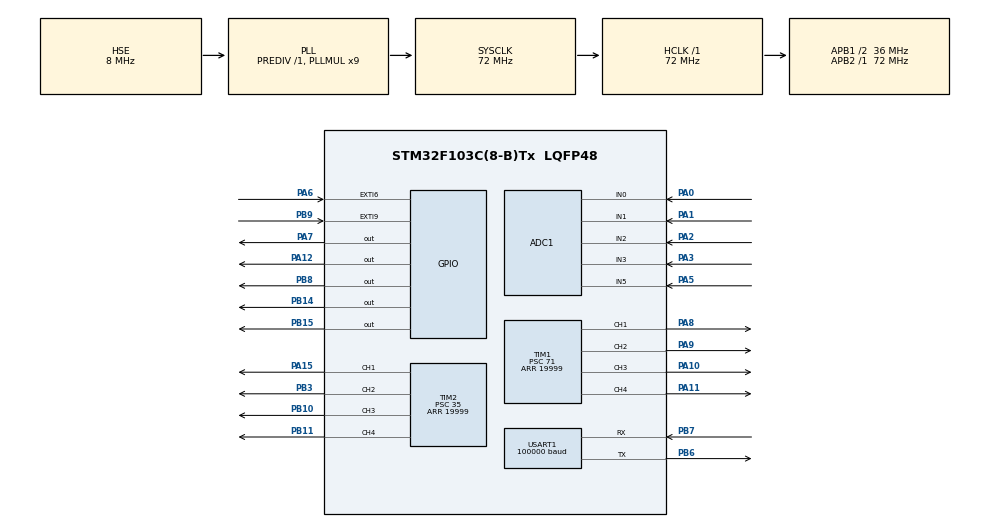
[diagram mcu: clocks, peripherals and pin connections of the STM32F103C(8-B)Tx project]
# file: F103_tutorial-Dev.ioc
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ADC1.Channel-0\#ChannelRegularConversion=ADC_CHANNEL_5
ADC1.NbrOfConversionFlag=1
ADC1.Rank-0\#ChannelRegularConversion=1
ADC1.SamplingTime-0\#ChannelRegularConversion=ADC_SAMPLETIME_1CYCLE_5
ADC1.master=1
Dma.Request0=USART1_RX
Dma.USART1_RX.0.Direction=DMA_PERIPH_TO_MEMORY
Dma.USART1_RX.0.Instance=DMA1_Channel5
Dma.USART1_RX.0.MemDataAlignment=DMA_MDATAALIGN_BYTE
Dma.USART1_RX.0.MemInc=DMA_MINC_ENABLE
Dma.USART1_RX.0.Mode=DMA_NORMAL
Dma.USART1_RX.0.PeriphDataAlignment=DMA_PDATAALIGN_BYTE
Dma.USART1_RX.0.PeriphInc=DMA_PINC_DISABLE
Dma.USART1_RX.0.Priority=DMA_PRIORITY_VERY_HIGH
FREERTOS.Tasks01=defaultTask,24,128,StartDefaultTask,Default,NULL,Dynamic,NULL,NULL
Mcu.Family=STM32F1
Mcu.Name=STM32F103C(8-B)Tx
Mcu.Package=LQFP48
NVIC.DMA1_Channel5_IRQn=true\:5\:0\:false\:false\:true\:true\:false\:true\:true
NVIC.EXTI9_5_IRQn=true\:5\:0\:false\:false\:true\:false\:true\:true\:true
NVIC.PriorityGroup=NVIC_PRIORITYGROUP_4
NVIC.TIM3_IRQn=true\:15\:0\:false\:false\:true\:false\:false\:true\:true
NVIC.TimeBase=TIM3_IRQn
NVIC.TimeBaseIP=TIM3
NVIC.USART1_IRQn=true\:5\:0\:false\:false\:true\:true\:true\:true\:true
PA0-WKUP.Signal=ADCx_IN0
PA1.Signal=ADCx_IN1
PA10.Signal=S_TIM1_CH3
PA11.Signal=S_TIM1_CH4
PA12.Signal=GPIO_Output
PA13.Mode=Serial_Wire
PA13.Signal=SYS_JTMS-SWDIO
PA14.Mode=Serial_Wire
PA14.Signal=SYS_JTCK-SWCLK
PA15.Signal=S_TIM2_CH1_ETR
PA2.Signal=ADCx_IN2
PA3.Signal=ADCx_IN3
PA5.Signal=ADCx_IN5
PA6.Signal=GPXTI6
PA7.Signal=GPIO_Output
PA8.Signal=S_TIM1_CH1
PA9.Signal=S_TIM1_CH2
PB10.Signal=S_TIM2_CH3
PB11.Signal=S_TIM2_CH4
PB14.Signal=GPIO_Output
PB15.Signal=GPIO_Output
PB3.Signal=S_TIM2_CH2
PB6.Mode=Asynchronous
PB6.Signal=USART1_TX
PB7.Mode=Asynchronous
PB7.Signal=USART1_RX
PB8.Signal=GPIO_Output
PB9.Signal=GPXTI9
PD0-OSC_IN.Mode=HSE-External-Oscillator
PD0-OSC_IN.Signal=RCC_OSC_IN
PD1-OSC_OUT.Mode=HSE-External-Oscillator
PD1-OSC_OUT.Signal=RCC_OSC_OUT
ProjectManager.HeapSize=0x200
ProjectManager.StackSize=0x400
ProjectManager.TargetToolchain=MDK-ARM V5.32
RCC.ADCPresc=RCC_ADCPCLK2_DIV6
RCC.AHBFreq_Value=72000000
RCC.APB1CLKDivider=RCC_HCLK_DIV2
RCC.APB1Freq_Value=36000000
RCC.APB1TimFreq_Value=72000000
RCC.APB2Freq_Value=72000000
RCC.APB2TimFreq_Value=72000000
RCC.HCLKFreq_Value=72000000
RCC.PLLMUL=RCC_PLL_MUL9
RCC.PLLSourceVirtual=RCC_PLLSOURCE_HSE
RCC.SYSCLKFreq_VALUE=72000000
RCC.SYSCLKSource=RCC_SYSCLKSOURCE_PLLCLK
RCC.USBFreq_Value=72000000
SH.ADCx_IN0.0=ADC1_IN0,IN0
SH.ADCx_IN1.0=ADC1_IN1,IN1
SH.ADCx_IN2.0=ADC1_IN2,IN2
SH.ADCx_IN3.0=ADC1_IN3,IN3
SH.ADCx_IN5.0=ADC1_IN5,IN5
SH.S_TIM1_CH1.0=TIM1_CH1,PWM Generation1 CH1
SH.S_TIM1_CH2.0=TIM1_CH2,PWM Generation2 CH2
SH.S_TIM1_CH3.0=TIM1_CH3,PWM Generation3 CH3
SH.S_TIM1_CH4.0=TIM1_CH4,PWM Generation4 CH4
SH.S_TIM2_CH1_ETR.0=TIM2_CH1,PWM Generation1 CH1
SH.S_TIM2_CH2.0=TIM2_CH2,PWM Generation2 CH2
SH.S_TIM2_CH3.0=TIM2_CH3,PWM Generation3 CH3
SH.S_TIM2_CH4.0=TIM2_CH4,PWM Generation4 CH4
TIM1.Channel-PWM\ Generation1\ CH1=TIM_CHANNEL_1
TIM1.Channel-PWM\ Generation2\ CH2=TIM_CHANNEL_2
TIM1.Channel-PWM\ Generation3\ CH3=TIM_CHANNEL_3
TIM1.Channel-PWM\ Generation4\ CH4=TIM_CHANNEL_4
TIM1.Period=19999
TIM1.Prescaler=71
TIM1.Pulse-PWM\ Generation1\ CH1=2000
TIM1.Pulse-PWM\ Generation2\ CH2=2000
TIM1.Pulse-PWM\ Generation3\ CH3=2000
TIM1.Pulse-PWM\ Generation4\ CH4=2000
TIM2.Channel-PWM\ Generation1\ CH1=TIM_CHANNEL_1
TIM2.Channel-PWM\ Generation2\ CH2=TIM_CHANNEL_2
TIM2.Channel-PWM\ Generation3\ CH3=TIM_CHANNEL_3
TIM2.Channel-PWM\ Generation4\ CH4=TIM_CHANNEL_4
TIM2.Period=19999
TIM2.Prescaler=35
TIM2.Pulse-PWM\ Generation1\ CH1=2000
TIM2.Pulse-PWM\ Generation2\ CH2=2000
TIM2.Pulse-PWM\ Generation3\ CH3=2000
TIM2.Pulse-PWM\ Generation4\ CH4=2000
USART1.BaudRate=100000
USART1.Parity=PARITY_EVEN
USART1.VirtualMode=VM_ASYNC
USART1.WordLength=WORDLENGTH_9B
VP_FREERTOS_VS_CMSIS_V2.Mode=CMSIS_V2
VP_SYS_VS_tim3.Mode=TIM3
board=custom

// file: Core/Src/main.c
/* USER CODE BEGIN Header */
/**
  ******************************************************************************
  * @file           : main.c
  * @brief          : Main program body
  ******************************************************************************
  * @attention
  *
  * Copyright (c) 2022 STMicroelectronics.
  * All rights reserved.
  *
  * This software is licensed under terms that can be found in the LICENSE file
  * in the root directory of this software component.
  * If no LICENSE file comes with this software, it is provided AS-IS.
  *
  ******************************************************************************
  */
/* USER CODE END Header */
#include "main.h"
#include "cmsis_os.h"
#include "adc.h"
#include "dma.h"
#include "tim.h"
#include "usart.h"
#include "gpio.h"

/* USER CODE BEGIN Includes */
#include "components.h"
/* USER CODE END Includes */

void SystemClock_Config(void);
void MX_FREERTOS_Init(void);

int main(void)
{

  /* MCU Configuration--------------------------------------------------------*/

  /* Reset of all peripherals, Initializes the Flash interface and the Systick. */
  HAL_Init();

  /* Configure the system clock */
  SystemClock_Config();

  /* Initialize all configured peripherals */
  MX_GPIO_Init();
  MX_DMA_Init();
  MX_ADC1_Init();
  MX_TIM1_Init();
  MX_TIM2_Init();
  MX_USART1_UART_Init();
  /* USER CODE BEGIN 2 */
	/*This function initializes all components initializers*/
	Components_Init();
	HAL_ADCEx_Calibration_Start(&hadc1);
  /* USER CODE END 2 */

  /* Init scheduler */
  osKernelInitialize();  /* Call init function for freertos objects (in freertos.c) */
  MX_FREERTOS_Init();

  /* Start scheduler */
  osKernelStart();

  /* We should never get here as control is now taken by the scheduler */
  /* Infinite loop */
  while (1)
  {

  }
}

void SystemClock_Config(void)
{
  RCC_OscInitTypeDef RCC_OscInitStruct = {0};
  RCC_ClkInitTypeDef RCC_ClkInitStruct = {0};
  RCC_PeriphCLKInitTypeDef PeriphClkInit = {0};

  /** Initializes the RCC Oscillators according to the specified parameters
  * in the RCC_OscInitTypeDef structure.
  */
  RCC_OscInitStruct.OscillatorType = RCC_OSCILLATORTYPE_HSE;
  RCC_OscInitStruct.HSEState = RCC_HSE_ON;
  RCC_OscInitStruct.HSEPredivValue = RCC_HSE_PREDIV_DIV1;
  RCC_OscInitStruct.HSIState = RCC_HSI_ON;
  RCC_OscInitStruct.PLL.PLLState = RCC_PLL_ON;
  RCC_OscInitStruct.PLL.PLLSource = RCC_PLLSOURCE_HSE;
  RCC_OscInitStruct.PLL.PLLMUL = RCC_PLL_MUL9;
  if (HAL_RCC_OscConfig(&RCC_OscInitStruct) != HAL_OK)
  {
    Error_Handler();
  }

  /** Initializes the CPU, AHB and APB buses clocks
  */
  RCC_ClkInitStruct.ClockType = RCC_CLOCKTYPE_HCLK|RCC_CLOCKTYPE_SYSCLK
                              |RCC_CLOCKTYPE_PCLK1|RCC_CLOCKTYPE_PCLK2;
  RCC_ClkInitStruct.SYSCLKSource = RCC_SYSCLKSOURCE_PLLCLK;
  RCC_ClkInitStruct.AHBCLKDivider = RCC_SYSCLK_DIV1;
  RCC_ClkInitStruct.APB1CLKDivider = RCC_HCLK_DIV2;
  RCC_ClkInitStruct.APB2CLKDivider = RCC_HCLK_DIV1;

  if (HAL_RCC_ClockConfig(&RCC_ClkInitStruct, FLASH_LATENCY_2) != HAL_OK)
  {
    Error_Handler();
  }
  PeriphClkInit.PeriphClockSelection = RCC_PERIPHCLK_ADC;
  PeriphClkInit.AdcClockSelection = RCC_ADCPCLK2_DIV6;
  if (HAL_RCCEx_PeriphCLKConfig(&PeriphClkInit) != HAL_OK)
  {
    Error_Handler();
  }
}

void HAL_TIM_PeriodElapsedCallback(TIM_HandleTypeDef *htim)
{
  if (htim->Instance == TIM3) {
    HAL_IncTick();
  }
}

void Error_Handler(void)
{
  __disable_irq();
  while (1)
  {
  }
}

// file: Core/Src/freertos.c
/* USER CODE BEGIN Header */
/**
  ******************************************************************************
  * File Name          : freertos.c
  * Description        : Code for freertos applications
  ******************************************************************************
  * @attention
  *
  * Copyright (c) 2022 STMicroelectronics.
  * All rights reserved.
  *
  * This software is licensed under terms that can be found in the LICENSE file
  * in the root directory of this software component.
  * If no LICENSE file comes with this software, it is provided AS-IS.
  *
  ******************************************************************************
  */
/* USER CODE END Header */

#include "FreeRTOS.h"
#include "task.h"
#include "main.h"
#include "cmsis_os.h"

/* USER CODE BEGIN Includes */
#include "user_main.h"
/* USER CODE END Includes */

/* Definitions for defaultTask */
osThreadId_t defaultTaskHandle;
const osThreadAttr_t defaultTask_attributes = {
  .name = "defaultTask",
  .stack_size = 128 * 4,
  .priority = (osPriority_t) osPriorityNormal,
};

void StartDefaultTask(void *argument);

void MX_FREERTOS_Init(void); /* (MISRA C 2004 rule 8.1) */

void MX_FREERTOS_Init(void) {

  /* Create the thread(s) */
  /* creation of defaultTask */
  defaultTaskHandle = osThreadNew(StartDefaultTask, NULL, &defaultTask_attributes);

  /* USER CODE BEGIN RTOS_THREADS */
  /* add threads, ... */
	User_Init();
  /* USER CODE END RTOS_THREADS */

}

void StartDefaultTask(void *argument)
{
  for(;;)
  {
    osDelay(1);
  }
}
